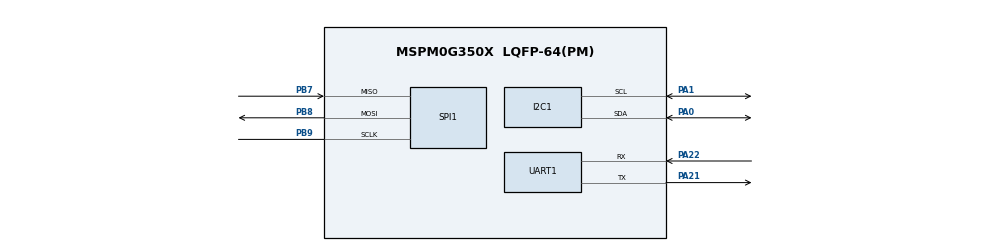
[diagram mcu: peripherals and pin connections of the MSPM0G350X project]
/**
 * @cliArgs --device "MSPM0G350X" --package "LQFP-64(PM)" --part "Default" --product "mspm0_sdk@2.00.01.00"
 * @versions {"tool":"1.20.0+3587"}
 */

/**
 * Import the modules used in this configuration.
 */
const I2C    = scripting.addModule("/ti/driverlib/I2C", {}, false);
const I2C1   = I2C.addInstance();
const SPI    = scripting.addModule("/ti/driverlib/SPI", {}, false);
const SPI1   = SPI.addInstance();
const SYSCTL = scripting.addModule("/ti/driverlib/SYSCTL");
const UART   = scripting.addModule("/ti/driverlib/UART", {}, false);
const UART1  = UART.addInstance();

/**
 * Write custom configuration values to the imported modules.
 */
I2C1.basicEnableController             = true;
I2C1.$name                             = "I2C0";
I2C1.peripheral.$assign                = "I2C0";
I2C1.peripheral.sdaPin.$assign         = "PA0";
I2C1.peripheral.sclPin.$assign         = "PA1";
I2C1.sdaPinConfig.$name                = "ti_driverlib_gpio_GPIOPinGeneric5";
I2C1.sdaPinConfig.hideOutputInversion  = scripting.forceWrite(false);
I2C1.sdaPinConfig.onlyInternalResistor = scripting.forceWrite(false);
I2C1.sdaPinConfig.passedPeripheralType = scripting.forceWrite("Digital");
I2C1.sclPinConfig.$name                = "ti_driverlib_gpio_GPIOPinGeneric6";
I2C1.sclPinConfig.hideOutputInversion  = scripting.forceWrite(false);
I2C1.sclPinConfig.onlyInternalResistor = scripting.forceWrite(false);
I2C1.sclPinConfig.passedPeripheralType = scripting.forceWrite("Digital");

const Board = scripting.addModule("/ti/driverlib/Board", {}, false);

SPI1.$name                              = "SPI1";
SPI1.targetBitRate                      = 800000;
SPI1.frameFormat                        = "MOTO3";
SPI1.peripheral.$assign                 = "SPI1";
SPI1.peripheral.sclkPin.$assign         = "PB9";
SPI1.peripheral.mosiPin.$assign         = "PB8";
SPI1.peripheral.misoPin.$assign         = "PB7";
SPI1.sclkPinConfig.$name                = "ti_driverlib_gpio_GPIOPinGeneric0";
SPI1.sclkPinConfig.direction            = scripting.forceWrite("OUTPUT");
SPI1.sclkPinConfig.onlyInternalResistor = scripting.forceWrite(false);
SPI1.sclkPinConfig.passedPeripheralType = scripting.forceWrite("Digital");
SPI1.mosiPinConfig.$name                = "ti_driverlib_gpio_GPIOPinGeneric1";
SPI1.mosiPinConfig.direction            = scripting.forceWrite("OUTPUT");
SPI1.mosiPinConfig.hideOutputInversion  = scripting.forceWrite(false);
SPI1.mosiPinConfig.onlyInternalResistor = scripting.forceWrite(false);
SPI1.mosiPinConfig.passedPeripheralType = scripting.forceWrite("Digital");
SPI1.misoPinConfig.$name                = "ti_driverlib_gpio_GPIOPinGeneric2";
SPI1.misoPinConfig.onlyInternalResistor = scripting.forceWrite(false);
SPI1.misoPinConfig.passedPeripheralType = scripting.forceWrite("Digital");

SYSCTL.forceDefaultClkConfig = true;

UART1.$name                    = "UART_0";
UART1.peripheral.$assign       = "UART2";
UART1.peripheral.rxPin.$assign = "PA22";
UART1.peripheral.txPin.$assign = "PA21";
UART1.txPinConfig.$name        = "ti_driverlib_gpio_GPIOPinGeneric3";
UART1.rxPinConfig.$name        = "ti_driverlib_gpio_GPIOPinGeneric4";

/**
 * Pinmux solution for unlocked pins/peripherals. This ensures that minor changes to the automatic solver in a future
 * version of the tool will not impact the pinmux you originally saw.  These lines can be completely deleted in order to
 * re-solve from scratch.
 */
Board.peripheral.$suggestSolution          = "DEBUGSS";
Board.peripheral.swclkPin.$suggestSolution = "PA20";
Board.peripheral.swdioPin.$suggestSolution = "PA19";
SYSCTL.peripheral.$suggestSolution         = "SYSCTL";
